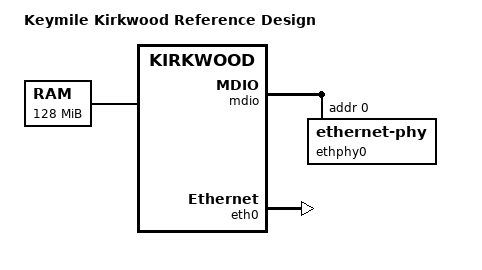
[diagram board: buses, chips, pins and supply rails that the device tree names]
// SPDX-License-Identifier: GPL-2.0
/dts-v1/;

#include "kirkwood.dtsi"
#include "kirkwood-98dx4122.dtsi"
#include "kirkwood-km_common.dtsi"

/ {
	model = "Keymile Kirkwood Reference Design";
	compatible = "keymile,km_kirkwood", "marvell,kirkwood-98DX4122", "marvell,kirkwood";

	memory {
		device_type = "memory";
		reg = <0x00000000 0x08000000>;
	};
};

&mdio {
	status = "okay";

	ethphy0: ethernet-phy@0 {
		reg = <0>;
	};
};

&eth0 {
	status = "okay";
	ethernet0-port@0 {
		phy-handle = <&ethphy0>;
	};
};
